# CY8C3245AXI_158 register map
File version: 0.1
CY8C32
Registers are 8-bit, read-write, no defined reset value unless marked. A register's access mark holds for its fields unless they carry their own. Offsets are from the block's base; lines under a group give offsets from that group; [hi:lo] are bit positions; {n}, {i} and the like mark numbered series; 'fields as' and 'values as' point back to an identical list; <NAME> marks a mode.

## Memory map
0x00000000 LIN_1
0x00000000 LIN_1_UART — UART
0x00000000 UART_Servo — UART
0x00000000 UART_Debug — UART

## LIN_1
Base 0x00000000
0x6429 INACT_INACTIVITY_DIV0_REG — Bus Inactivity Divider 0 Register
  [7:0] LIN_1_INACTIVITY_DIV0 — ((Baud Rate * 16 (oversampling) / 10 (100 ms)) / 256) - 1
0x6439 INACT_INACTIVITY_DIV1_REG — Bus Inactivity Divider 1 Register
  [7:0] LIN_1_INACTIVITY_DIV1 — (Baud Rate * 16 (oversampling) / 10 (100 ms)) % 256
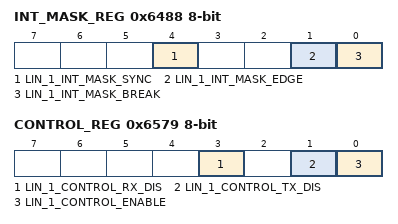
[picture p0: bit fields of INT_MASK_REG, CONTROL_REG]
0x6488 INT_MASK_REG — Status Mask Register
  [4] LIN_1_INT_MASK_SYNC — Sync field detected mask
  [1] LIN_1_INT_MASK_EDGE — Edge detected mask
  [0] LIN_1_INT_MASK_BREAK — Break field threshold detected mask
0x6528 BREAK_THRESHOLD_REG — Break Threshold Register
  [7:0] LIN_1_BREAK_THRESHOLD — Break threshold detection value assuming 16x oversampling
0x6579 CONTROL_REG — Control Register
  [3] LIN_1_CONTROL_RX_DIS — Disconnect RX from LIN bus
  [1] LIN_1_CONTROL_TX_DIS — Force TX pin low
  [0] LIN_1_CONTROL_ENABLE — Enable base LIN operation

## LIN_1_UART — UART
Base 0x00000000
0x6426 RX_LIN_1_UART_RX_ADDRESS1 — RX Address1 Register
0x6436 RX_LIN_1_UART_RX_ADDRESS2 — RX Address2 Register
0x6440 TX_LIN_1_UART_TX_DATA — TX Data Register
0x6446 RX_LIN_1_UART_RX_DATA — RX Data Register
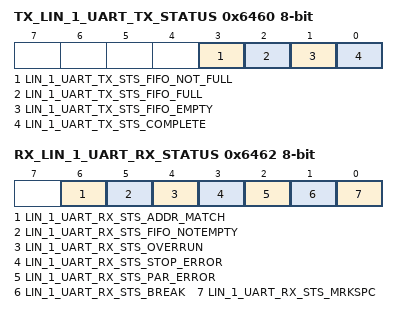
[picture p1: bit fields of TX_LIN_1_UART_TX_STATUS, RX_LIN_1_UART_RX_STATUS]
0x6460 TX_LIN_1_UART_TX_STATUS — TX status register
  [3] LIN_1_UART_TX_STS_FIFO_NOT_FULL ro, [2] LIN_1_UART_TX_STS_FIFO_FULL ro, [1] LIN_1_UART_TX_STS_FIFO_EMPTY ro, [0] LIN_1_UART_TX_STS_COMPLETE ro
0x6462 RX_LIN_1_UART_RX_STATUS — RX status register
  [6] LIN_1_UART_RX_STS_ADDR_MATCH ro, [5] LIN_1_UART_RX_STS_FIFO_NOTEMPTY ro, [4] LIN_1_UART_RX_STS_OVERRUN ro, [3] LIN_1_UART_RX_STS_STOP_ERROR ro, [2] LIN_1_UART_RX_STS_PAR_ERROR ro, [1] LIN_1_UART_RX_STS_BREAK ro, [0] LIN_1_UART_RX_STS_MRKSPC ro

## UART_Servo — UART
Base 0x00000000
0x6427 RX_UART_Servo_RX_ADDRESS1 — RX Address1 Register
0x6437 RX_UART_Servo_RX_ADDRESS2 — RX Address2 Register
0x6447 RX_UART_Servo_RX_DATA — RX Data Register
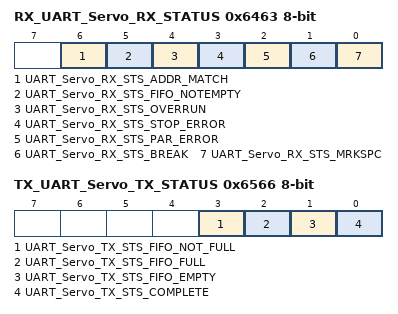
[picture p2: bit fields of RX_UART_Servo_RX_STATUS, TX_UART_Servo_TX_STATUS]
0x6463 RX_UART_Servo_RX_STATUS — RX status register
  [6] UART_Servo_RX_STS_ADDR_MATCH ro, [5] UART_Servo_RX_STS_FIFO_NOTEMPTY ro, [4] UART_Servo_RX_STS_OVERRUN ro, [3] UART_Servo_RX_STS_STOP_ERROR ro, [2] UART_Servo_RX_STS_PAR_ERROR ro, [1] UART_Servo_RX_STS_BREAK ro, [0] UART_Servo_RX_STS_MRKSPC ro
0x6546 TX_UART_Servo_TX_DATA — TX Data Register
0x6566 TX_UART_Servo_TX_STATUS — TX status register
  [3] UART_Servo_TX_STS_FIFO_NOT_FULL ro, [2] UART_Servo_TX_STS_FIFO_FULL ro, [1] UART_Servo_TX_STS_FIFO_EMPTY ro, [0] UART_Servo_TX_STS_COMPLETE ro

## UART_Debug — UART
Base 0x00000000
0x6443 TX_UART_Debug_TX_DATA — TX Data Register
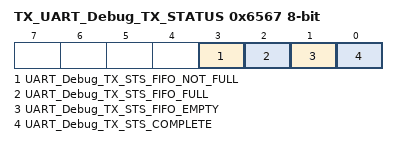
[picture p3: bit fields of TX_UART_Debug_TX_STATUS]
0x6567 TX_UART_Debug_TX_STATUS — TX status register
  [3] UART_Debug_TX_STS_FIFO_NOT_FULL ro, [2] UART_Debug_TX_STS_FIFO_FULL ro, [1] UART_Debug_TX_STS_FIFO_EMPTY ro, [0] UART_Debug_TX_STS_COMPLETE ro
